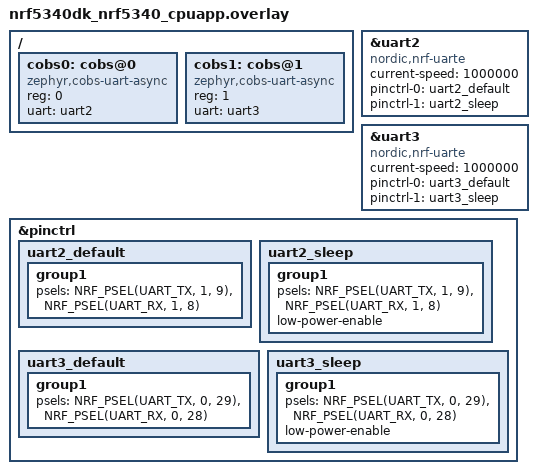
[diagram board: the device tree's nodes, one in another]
/*
 * Copyright (c) 2024 Nordic Semiconductor ASA
 *
 * SPDX-License-Identifier: Apache-2.0
 */

/ {
	#size-cells = <0>;

	cobs0: cobs@0 {
		compatible = "zephyr,cobs-uart-async";
		reg = <0>;
		uart = <&uart2>;
		status = "okay";
	};

	cobs1: cobs@1 {
		compatible = "zephyr,cobs-uart-async";
		reg = <1>;
		uart = <&uart3>;
		status = "okay";
	};
};

/* Configure UART2 for first SLIP interface */
&uart2 {
	compatible = "nordic,nrf-uarte";
	status = "okay";
	current-speed = <1000000>;
	pinctrl-0 = <&uart2_default>;
	pinctrl-1 = <&uart2_sleep>;
	pinctrl-names = "default", "sleep";
};

/* Configure UART3 for second SLIP interface */
&uart3 {
	compatible = "nordic,nrf-uarte";
	status = "okay";
	current-speed = <1000000>;
	pinctrl-0 = <&uart3_default>;
	pinctrl-1 = <&uart3_sleep>;
	pinctrl-names = "default", "sleep";
};

&pinctrl {
	/* UART2: P1.08 (RX), P1.09 (TX) */
	uart2_default: uart2_default {
		group1 {
			psels = <NRF_PSEL(UART_TX, 1, 9)>,
				<NRF_PSEL(UART_RX, 1, 8)>;
		};
	};

	uart2_sleep: uart2_sleep {
		group1 {
			psels = <NRF_PSEL(UART_TX, 1, 9)>,
				<NRF_PSEL(UART_RX, 1, 8)>;
			low-power-enable;
		};
	};

	/* UART3: P0.28 (RX), P0.29 (TX) */
	uart3_default: uart3_default {
		group1 {
			psels = <NRF_PSEL(UART_TX, 0, 29)>,
				<NRF_PSEL(UART_RX, 0, 28)>;
		};
	};

	uart3_sleep: uart3_sleep {
		group1 {
			psels = <NRF_PSEL(UART_TX, 0, 29)>,
				<NRF_PSEL(UART_RX, 0, 28)>;
			low-power-enable;
		};
	};
};

